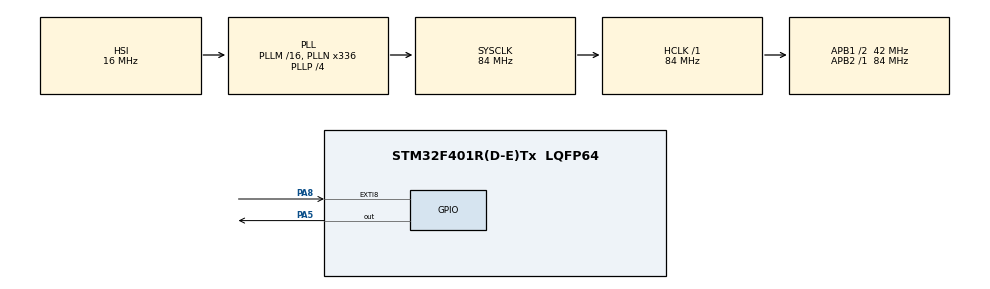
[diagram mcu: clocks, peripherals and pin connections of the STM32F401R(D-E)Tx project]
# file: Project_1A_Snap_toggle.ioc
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Mcu.Family=STM32F4
Mcu.Name=STM32F401R(D-E)Tx
Mcu.Package=LQFP64
NVIC.EXTI9_5_IRQn=true\:5\:0\:true\:false\:true\:true\:true
NVIC.PriorityGroup=NVIC_PRIORITYGROUP_4
NVIC.TIM1_UP_TIM10_IRQn=true\:0\:0\:false\:false\:true\:false\:true
NVIC.TimeBase=TIM1_UP_TIM10_IRQn
NVIC.TimeBaseIP=TIM1
PA13.GPIO_Label=TMS
PA13.Mode=Serial_Wire
PA13.Signal=SYS_JTMS-SWDIO
PA14.GPIO_Label=TCK
PA14.Mode=Serial_Wire
PA14.Signal=SYS_JTCK-SWCLK
PA5.Signal=GPIO_Output
PA8.GPIO_ModeDefaultEXTI=GPIO_MODE_IT_RISING
PA8.Signal=GPXTI8
PB3.GPIO_Label=SWO
PB3.Signal=SYS_JTDO-SWO
ProjectManager.HeapSize=0x200
ProjectManager.StackSize=0x400
ProjectManager.TargetToolchain=MDK-ARM V5
RCC.48MHZClocksFreq_Value=48000000
RCC.AHBFreq_Value=84000000
RCC.APB1CLKDivider=RCC_HCLK_DIV2
RCC.APB1Freq_Value=42000000
RCC.APB1TimFreq_Value=84000000
RCC.APB2Freq_Value=84000000
RCC.APB2TimFreq_Value=84000000
RCC.CortexFreq_Value=84000000
RCC.HCLKFreq_Value=84000000
RCC.HSE_VALUE=8000000
RCC.HSI_VALUE=16000000
RCC.LSE_VALUE=32768
RCC.PLLN=336
RCC.PLLP=RCC_PLLP_DIV4
RCC.PLLQ=7
RCC.SYSCLKFreq_VALUE=84000000
RCC.SYSCLKSource=RCC_SYSCLKSOURCE_PLLCLK
RCC.VCOOutputFreq_Value=336000000
VP_SYS_VS_tim1.Mode=TIM1
board=NUCLEO-F401RE

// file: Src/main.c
/* USER CODE BEGIN Header */
/**
  ******************************************************************************
  * @file           : main.c
  * @brief          : Main program body
  ******************************************************************************
  * @attention
  *
  * <h2><center>&copy; Copyright (c) 2019 STMicroelectronics.
  * All rights reserved.</center></h2>
  *
  * This software component is licensed by ST under Ultimate Liberty license
  * SLA0044, the "License"; You may not use this file except in compliance with
  * the License. You may obtain a copy of the License at:
  *                             www.st.com/SLA0044
  *
  ******************************************************************************
  */
/* USER CODE END Header */

#include "main.h"

void SystemClock_Config(void);
static void MX_GPIO_Init(void);

int main(void)
{

  /* MCU Configuration--------------------------------------------------------*/

  /* Reset of all peripherals, Initializes the Flash interface and the Systick. */
  HAL_Init();

  /* Configure the system clock */
  SystemClock_Config();

  /* Initialize all configured peripherals */
  MX_GPIO_Init();

  /* Infinite loop */
  while (1)
  {

  }
}

void SystemClock_Config(void)
{
  RCC_OscInitTypeDef RCC_OscInitStruct = {0};
  RCC_ClkInitTypeDef RCC_ClkInitStruct = {0};

  /** Configure the main internal regulator output voltage
  */
  __HAL_RCC_PWR_CLK_ENABLE();
  __HAL_PWR_VOLTAGESCALING_CONFIG(PWR_REGULATOR_VOLTAGE_SCALE2);
  /** Initializes the CPU, AHB and APB busses clocks
  */
  RCC_OscInitStruct.OscillatorType = RCC_OSCILLATORTYPE_HSI;
  RCC_OscInitStruct.HSIState = RCC_HSI_ON;
  RCC_OscInitStruct.HSICalibrationValue = RCC_HSICALIBRATION_DEFAULT;
  RCC_OscInitStruct.PLL.PLLState = RCC_PLL_ON;
  RCC_OscInitStruct.PLL.PLLSource = RCC_PLLSOURCE_HSI;
  RCC_OscInitStruct.PLL.PLLM = 16;
  RCC_OscInitStruct.PLL.PLLN = 336;
  RCC_OscInitStruct.PLL.PLLP = RCC_PLLP_DIV4;
  RCC_OscInitStruct.PLL.PLLQ = 7;
  if (HAL_RCC_OscConfig(&RCC_OscInitStruct) != HAL_OK)
  {
    Error_Handler();
  }
  /** Initializes the CPU, AHB and APB busses clocks
  */
  RCC_ClkInitStruct.ClockType = RCC_CLOCKTYPE_HCLK|RCC_CLOCKTYPE_SYSCLK
                              |RCC_CLOCKTYPE_PCLK1|RCC_CLOCKTYPE_PCLK2;
  RCC_ClkInitStruct.SYSCLKSource = RCC_SYSCLKSOURCE_PLLCLK;
  RCC_ClkInitStruct.AHBCLKDivider = RCC_SYSCLK_DIV1;
  RCC_ClkInitStruct.APB1CLKDivider = RCC_HCLK_DIV2;
  RCC_ClkInitStruct.APB2CLKDivider = RCC_HCLK_DIV1;

  if (HAL_RCC_ClockConfig(&RCC_ClkInitStruct, FLASH_LATENCY_2) != HAL_OK)
  {
    Error_Handler();
  }
}

static void MX_GPIO_Init(void)
{
  GPIO_InitTypeDef GPIO_InitStruct = {0};

  /* GPIO Ports Clock Enable */
  __HAL_RCC_GPIOA_CLK_ENABLE();
  __HAL_RCC_GPIOB_CLK_ENABLE();

  /*Configure GPIO pin Output Level */
  HAL_GPIO_WritePin(GPIOA, GPIO_PIN_5, GPIO_PIN_RESET);

  /*Configure GPIO pin : PA5 */
  GPIO_InitStruct.Pin = GPIO_PIN_5;
  GPIO_InitStruct.Mode = GPIO_MODE_OUTPUT_PP;
  GPIO_InitStruct.Pull = GPIO_NOPULL;
  GPIO_InitStruct.Speed = GPIO_SPEED_FREQ_LOW;
  HAL_GPIO_Init(GPIOA, &GPIO_InitStruct);

  /*Configure GPIO pin : PA8 */
  GPIO_InitStruct.Pin = GPIO_PIN_8;
  GPIO_InitStruct.Mode = GPIO_MODE_IT_RISING;
  GPIO_InitStruct.Pull = GPIO_NOPULL;
  HAL_GPIO_Init(GPIOA, &GPIO_InitStruct);

  /* EXTI interrupt init*/
  HAL_NVIC_SetPriority(EXTI9_5_IRQn, 5, 0);
  HAL_NVIC_EnableIRQ(EXTI9_5_IRQn);

}

/* USER CODE BEGIN 4 */
void HAL_GPIO_EXTI_Callback(uint16_t GPIO_Pin)
{
	switch (GPIO_Pin)
	{
		case GPIO_PIN_8:
			HAL_GPIO_TogglePin(GPIOA, GPIO_PIN_5);
			HAL_Delay(200);
			__HAL_GPIO_EXTI_CLEAR_FLAG(GPIO_Pin);
		break;
	}
}
/* USER CODE END 4 */

void HAL_TIM_PeriodElapsedCallback(TIM_HandleTypeDef *htim)
{
  if (htim->Instance == TIM1) {
    HAL_IncTick();
  }
}

void Error_Handler(void)
{
}

/************************ (C) COPYRIGHT STMicroelectronics *****END OF FILE****/
